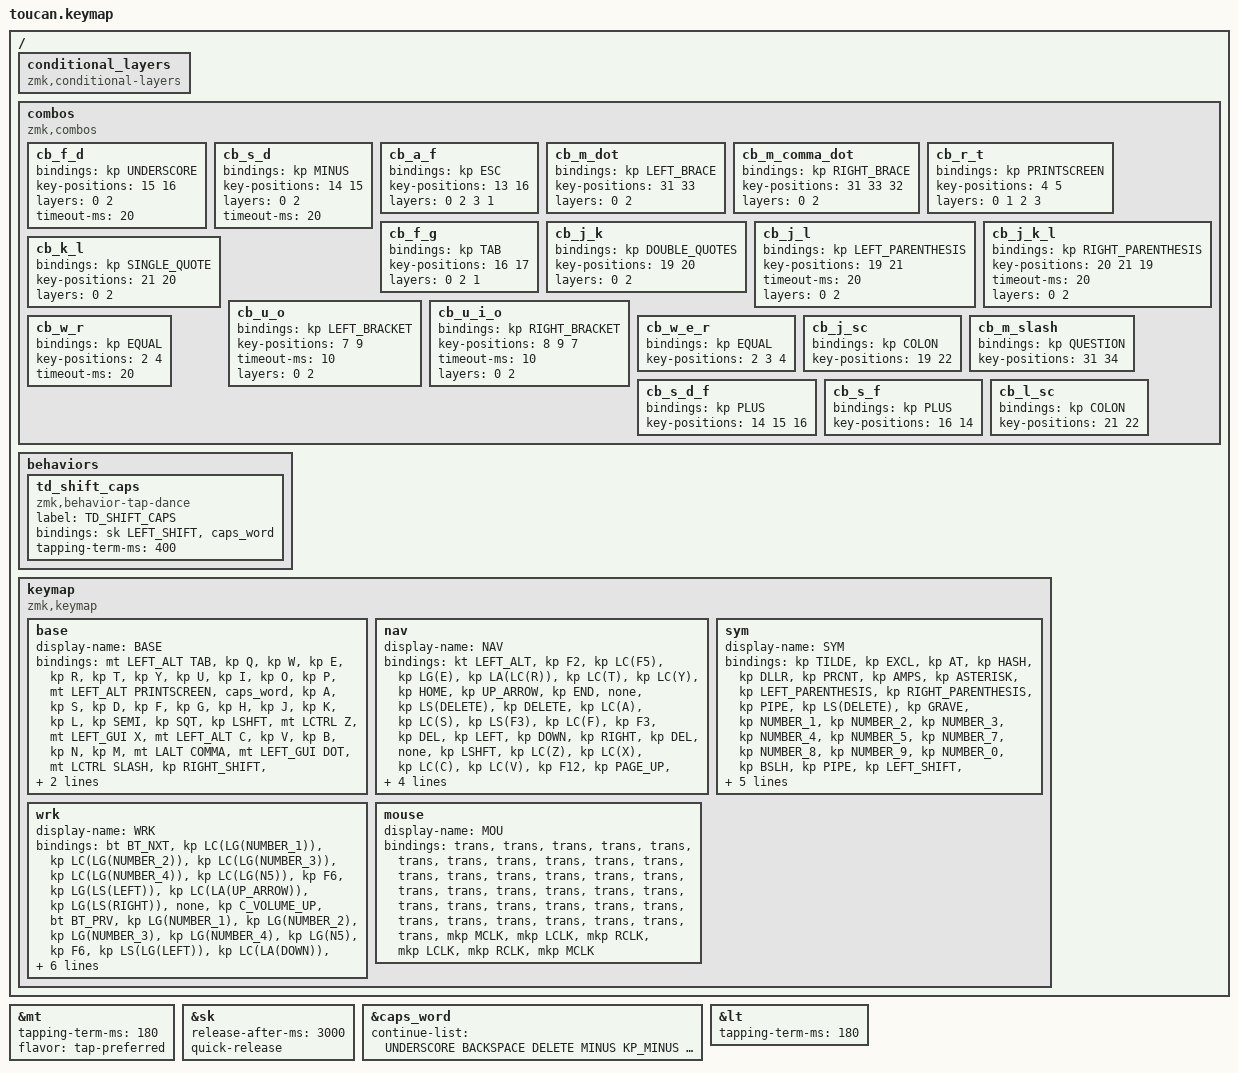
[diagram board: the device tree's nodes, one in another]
#include <behaviors.dtsi>
#include <dt-bindings/zmk/bt.h>
#include <dt-bindings/zmk/keys.h>
#include <dt-bindings/zmk/outputs.h>
#include <dt-bindings/zmk/pointing.h>

#define BASE 0
#define NAV  1
#define SYM  2
#define ADJ  3

&mt {
    tapping-term-ms = <180>;
    flavor = "tap-preferred";
};

&sk {
    release-after-ms = <3000>;
    quick-release;
};

&caps_word { continue-list = <UNDERSCORE BACKSPACE DELETE MINUS KP_MINUS LEFT_ARROW>; };

&lt { tapping-term-ms = <180>; };

/ {
    conditional_layers { compatible = "zmk,conditional-layers"; };

    combos {
        compatible = "zmk,combos";

        cb_f_d {
            bindings = <&kp UNDERSCORE>;
            key-positions = <15 16>;
            layers = <0 2>;
            timeout-ms = <20>;
        };

        cb_s_d {
            bindings = <&kp MINUS>;
            key-positions = <14 15>;
            layers = <0 2>;
            timeout-ms = <20>;
        };

        cb_a_f {
            bindings = <&kp ESC>;
            key-positions = <13 16>;
            layers = <0 2 3 1>;
        };

        cb_m_dot {
            bindings = <&kp LEFT_BRACE>;
            key-positions = <31 33>;
            layers = <0 2>;
        };

        cb_m_comma_dot {
            bindings = <&kp RIGHT_BRACE>;
            key-positions = <31 33 32>;
            layers = <0 2>;
        };

        cb_r_t {
            bindings = <&kp PRINTSCREEN>;
            key-positions = <4 5>;
            layers = <0 1 2 3>;
        };

        cb_f_g {
            bindings = <&kp TAB>;
            key-positions = <16 17>;
            layers = <0 2 1>;
        };

        cb_j_k {
            bindings = <&kp DOUBLE_QUOTES>;
            key-positions = <19 20>;
            layers = <0 2>;
        };

        cb_j_l {
            bindings = <&kp LEFT_PARENTHESIS>;
            key-positions = <19 21>;
            timeout-ms = <20>;
            layers = <0 2>;
        };

        cb_j_k_l {
            bindings = <&kp RIGHT_PARENTHESIS>;
            key-positions = <20 21 19>;
            timeout-ms = <20>;
            layers = <0 2>;
        };

        cb_k_l {
            bindings = <&kp SINGLE_QUOTE>;
            key-positions = <21 20>;
            layers = <0 2>;
        };

        cb_u_o {
            bindings = <&kp LEFT_BRACKET>;
            key-positions = <7 9>;
            timeout-ms = <10>;
            layers = <0 2>;
        };

        cb_u_i_o {
            bindings = <&kp RIGHT_BRACKET>;
            key-positions = <8 9 7>;
            timeout-ms = <10>;
            layers = <0 2>;
        };

        cb_w_r {
            bindings = <&kp EQUAL>;
            key-positions = <2 4>;
            timeout-ms = <20>;
        };

        cb_w_e_r {
            bindings = <&kp EQUAL>;
            key-positions = <2 3 4>;
        };

        cb_j_sc {
            bindings = <&kp COLON>;
            key-positions = <19 22>;
        };

        cb_m_slash {
            bindings = <&kp QUESTION>;
            key-positions = <31 34>;
        };

        cb_s_d_f {
            bindings = <&kp PLUS>;
            key-positions = <14 15 16>;
        };

        cb_s_f {
            bindings = <&kp PLUS>;
            key-positions = <16 14>;
        };

        cb_l_sc {
            bindings = <&kp COLON>;
            key-positions = <21 22>;
        };
    };

    behaviors {
        td_shift_caps: td_shift_caps {
            compatible = "zmk,behavior-tap-dance";
            label = "TD_SHIFT_CAPS";
            #binding-cells = <0>;
            bindings = <&sk LEFT_SHIFT>, <&caps_word>;

            tapping-term-ms = <400>;
        };
    };

    keymap {
        compatible = "zmk,keymap";

        base {
            display-name = "BASE";
            bindings = <
&mt LEFT_ALT TAB  &kp Q  &kp W  &kp E  &kp R  &kp T  &kp Y  &kp U  &kp I  &kp O  &kp P  &mt LEFT_ALT PRINTSCREEN  &caps_word  &kp A  &kp S  &kp D  &kp F  &kp G  &kp H  &kp J  &kp K  &kp L  &kp SEMI  &kp SQT  &kp LSHFT  &mt LCTRL Z  &mt LEFT_GUI X  &mt LEFT_ALT C  &kp V  &kp B  &kp N  &kp M  &mt LALT COMMA  &mt LEFT_GUI DOT  &mt LCTRL SLASH  &kp RIGHT_SHIFT  &lt 3 LEFT_GUI  &mo 1  &td_shift_caps  &kp RET  &lt 2 SPACE  &mo 1
            >;
        };

        nav {
            display-name = "NAV";
            bindings = <
&kt LEFT_ALT  &kp F2  &kp LC(F5)  &kp LG(E)  &kp LA(LC(R))  &kp LC(T)  &kp LC(Y)  &kp HOME  &kp UP_ARROW  &kp END  &none  &kp LS(DELETE)  &kp DELETE  &kp LC(A)  &kp LC(S)  &kp LS(F3)  &kp LC(F)  &kp F3  &kp DEL  &kp LEFT  &kp DOWN  &kp RIGHT  &kp DEL  &none  &kp LSHFT  &kp LC(Z)  &kp LC(X)  &kp LC(C)  &kp LC(V)  &kp F12  &kp PAGE_UP  &kp LS(LC(LEFT))  &none  &kp LS(LC(RIGHT))  &kp PAGE_DOWN  &kp RIGHT_SHIFT  &bootloader  &none  &studio_unlock  &kp LEFT_SHIFT  &kp BACKSPACE  &none
            >;
        };

        sym {
            display-name = "SYM";
            bindings = <
&kp TILDE  &kp EXCL  &kp AT  &kp HASH  &kp DLLR  &kp PRCNT  &kp AMPS  &kp ASTERISK  &kp LEFT_PARENTHESIS  &kp RIGHT_PARENTHESIS  &kp PIPE  &kp LS(DELETE)  &kp GRAVE  &kp NUMBER_1  &kp NUMBER_2  &kp NUMBER_3  &kp NUMBER_4  &kp NUMBER_5  &kp NUMBER_7  &kp NUMBER_8  &kp NUMBER_9  &kp NUMBER_0  &kp BSLH  &kp PIPE  &kp LEFT_SHIFT  &kp QUESTION  &kp LESS_THAN  &kp GT  &kp CARET  &kp NUMBER_6  &kp CARET  &kp QUESTION  &kp COMMA  &kp DOT  &kp SLASH  &kp RIGHT_SHIFT  &kp LGUI  &kp BACKSPACE  &mo 3  &kp K_MUTE  &none  &bootloader
            >;
        };

        wrk {
            display-name = "WRK";
            bindings = <
&bt BT_NXT  &kp LC(LG(NUMBER_1))  &kp LC(LG(NUMBER_2))  &kp LC(LG(NUMBER_3))  &kp LC(LG(NUMBER_4))  &kp LC(LG(N5))  &kp F6  &kp LG(LS(LEFT))  &kp LC(LA(UP_ARROW))  &kp LG(LS(RIGHT))  &none  &kp C_VOLUME_UP  &bt BT_PRV  &kp LG(NUMBER_1)  &kp LG(NUMBER_2)  &kp LG(NUMBER_3)  &kp LG(NUMBER_4)  &kp LG(N5)  &kp F6  &kp LS(LG(LEFT))  &kp LC(LA(DOWN))  &kp LS(LG(RIGHT))  &kp F12  &kp K_MUTE  &bt BT_CLR  &kp F1  &kp F2  &kp F3  &kp F4  &kp F5  &kp F7  &kp F8  &kp F9  &kp F10  &kp F11  &kp C_VOLUME_DOWN  &none  &out OUT_BLE  &out OUT_USB  &kp LCTRL  &kp LEFT_SHIFT  &kp RIGHT_SHIFT
            >;
        };

        mouse {
            display-name = "MOU";
            bindings = <
&trans  &trans  &trans  &trans  &trans  &trans  &trans  &trans  &trans  &trans  &trans  &trans  &trans  &trans  &trans  &trans  &trans  &trans  &trans  &trans  &trans  &trans  &trans  &trans  &trans  &trans  &trans  &trans  &trans  &trans  &trans  &trans  &trans  &trans  &trans  &trans  &mkp MCLK  &mkp LCLK  &mkp RCLK  &mkp LCLK  &mkp RCLK  &mkp MCLK
            >;
        };
    };
};
